# GD32L23x register map
File version: 1.0
CPU: CM23 r0p0, little endian, MPU, FPU, 4 interrupt priority bits
Registers are 32-bit, read-write, reset 0x0 unless marked. A register's access mark holds for its fields unless they carry their own. Offsets are from the block's base; [hi:lo] are bit positions.

## LPTIMER — Low power timers
Base 0x40009400
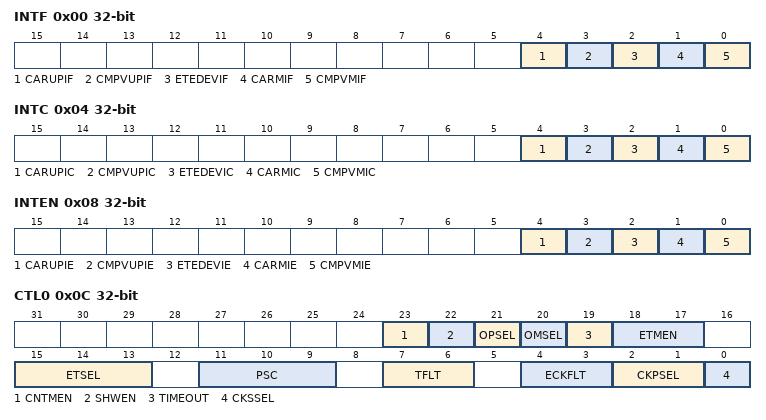
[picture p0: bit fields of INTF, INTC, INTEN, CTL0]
0x00 INTF ro — Interrupt flag register
  [4] CARUPIF — Counter auto reload register update interrupt flag
  [3] CMPVUPIF — Compare value register update interrupt flag
  [2] ETEDEVIF — External trigger edge event interrupt flag
  [1] CARMIF — Counter auto reload register match interrupt flag
  [0] CMPVMIF — Compare value register match interrupt flag
0x04 INTC — Interrupt flag clear register
  [4] CARUPIC — Counter auto reload register update interrupt flag clear
  [3] CMPVUPIC — Compare value register update interrupt flag clear
  [2] ETEDEVIC — External trigger edge event interrupt flag clear
  [1] CARMIC — Counter auto reload register match interrupt flag clear
  [0] CMPVMIC — Compare value register match interrupt flag clear
0x08 INTEN — Interrupt enable register
  [4] CARUPIE — Counter auto reload register update interrupt
  [3] CMPVUPIE — Compare value register update interrupt
  [2] ETEDEVIE — External trigger edge event interrupt
  [1] CARMIE — Counter auto reload register match interrupt
  [0] CMPVMIE — Compare value register match interrupt
0x0C CTL0 — Control register 0
  [23] CNTMEN — Counter mode select
  [22] SHWEN — LPTIMER_CAR and LPTIMER_CMPV shadow registers enable
  [21] OPSEL — Output polarity select
  [20] OMSEL — Output Mode select
  [19] TIMEOUT — Timeout enable
  [18:17] ETMEN — External Trigger mode enable
  [15:13] ETSEL — External trigger select
  [11:9] PSC — Clock prescaler selection
  [7:6] TFLT — Trigger filter
  [4:3] ECKFLT — External clock filter
  [2:1] CKPSEL — Clock polarity select
  [0] CKSSEL — Clock source select
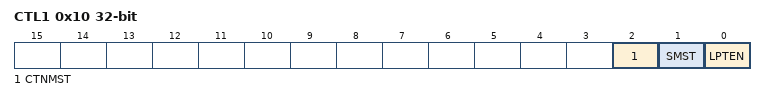
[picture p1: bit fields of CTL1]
0x10 CTL1 — Control register 1
  [2] CTNMST — LPTIMER start in continus counting mode.
  [1] SMST — LPTIMER start in single counting mode
  [0] LPTEN — LPTIMER enable
0x14 CMPV — Compare value register
  [31:0] CMPVAL — Compare value
0x18 CAR — Counter auto reload value
  [31:0] CARL — Low Auto-reload value
0x1C CNT — counter register
  [31:0] CNT — Low counter value
0x20 EIRMP — External input remap register
  [1:0] EI_RMP — External input remap 1

## LPUART — Low-power Universal synchronous asynchronous receiver transmitter
Base 0x40008000
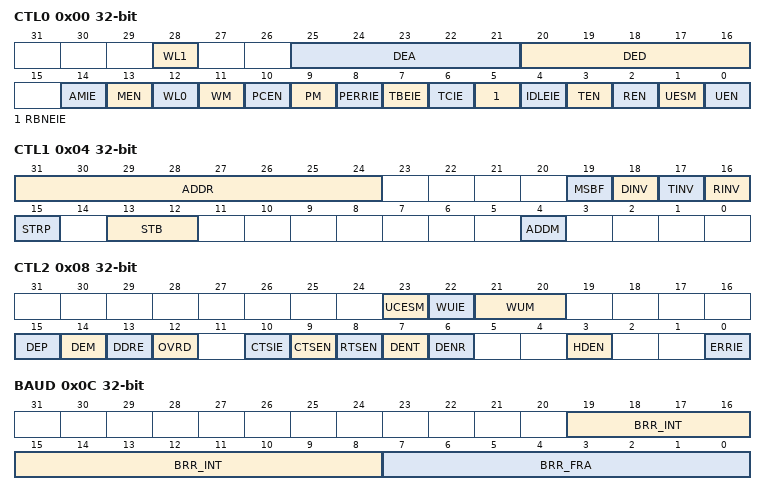
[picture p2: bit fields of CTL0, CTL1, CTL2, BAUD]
0x00 CTL0 — Control register 0
  [28] WL1 — Word length
  [25:21] DEA — Driver Enable assertion time
  [20:16] DED — Driver Enable deassertion time
  [14] AMIE — Character match interrupt enable
  [13] MEN — Mute mode enable
  [12] WL0 — Word length
  [11] WM — Receiver wakeup method
  [10] PCEN — Parity control enable
  [9] PM — Parity selection
  [8] PERRIE — PE interrupt enable
  [7] TBEIE — interrupt enable
  [6] TCIE — Transmission complete interrupt enable
  [5] RBNEIE — RXNE interrupt enable
  [4] IDLEIE — IDLE interrupt enable
  [3] TEN — Transmitter enable
  [2] REN — Receiver enable
  [1] UESM — LPUART enable in Deep-sleep mode
  [0] UEN — USART enable
0x04 CTL1 — Control register 1
  [31:24] ADDR — Address of the USART terminal
  [19] MSBF — Most significant bit first
  [18] DINV — Data bit level inversion
  [17] TINV — TX pin active level inversion
  [16] RINV — RX pin active level inversion
  [15] STRP — Swap TX/RX pins
  [13:12] STB — STOP bits
  [4] ADDM — 7-bit Address Detection/4-bit Address Detection
0x08 CTL2 — Control register 2
  [23] UCESM — LPUART clock enable in Deep-sleep mode
  [22] WUIE — Wakeup from Deep-sleep mode interrupt enable
  [21:20] WUM — Wakeup mode from Deep-sleep mode
  [15] DEP — Driver enable polarity selection
  [14] DEM — Driver enable mode
  [13] DDRE — DMA Disable on Reception Error
  [12] OVRD — Overrun Disable
  [10] CTSIE — CTS interrupt enable
  [9] CTSEN — CTS enable
  [8] RTSEN — RTS enable
  [7] DENT — DMA enable transmitter
  [6] DENR — DMA enable receiver
  [3] HDEN — Half-duplex selection
  [0] ERRIE — Error interrupt enable
0x0C BAUD — Baud rate low register
  [19:8] BRR_INT — integer of baud-rate divider
  [7:0] BRR_FRA — integer of baud-rate divider
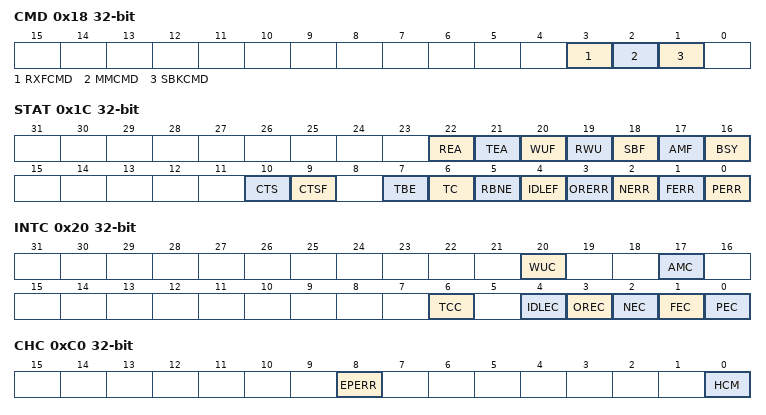
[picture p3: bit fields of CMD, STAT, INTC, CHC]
0x18 CMD wo — Command register
  [3] RXFCMD — Receive data flush command
  [2] MMCMD — Mute mode command
  [1] SBKCMD — Send break command
0x1C STAT ro — Status register
  [22] REA — Receive enable acknowledge flag
  [21] TEA — Transmit enable acknowledge flag
  [20] WUF — Wakeup from Deep-sleep mode flag
  [19] RWU — Receiver wakeup from mute mode
  [18] SBF — Send break flag
  [17] AMF — ADDR match flag
  [16] BSY — Busy flag
  [10] CTS — CTS leve
  [9] CTSF — CTS change flag
  [7] TBE — Transmit data register empty
  [6] TC — Transmission completed
  [5] RBNE — Read data buffer not empty
  [4] IDLEF — IDLE line detected flag
  [3] ORERR — Overrun error
  [2] NERR — Noise error flag
  [1] FERR — Frame error flag
  [0] PERR — Parity error flag
0x20 INTC wo — Interrupt status clear register
  [20] WUC — Wakeup from Deep-sleep mode flag clear
  [17] AMC — ADDR match flag clear
  [6] TCC — Transmission completed clear
  [4] IDLEC — IDLE line detected flag clear
  [3] OREC — Overrun error clear
  [2] NEC — Noise error flag clear
  [1] FEC — Frame error flag clear
  [0] PEC — Parity error flag clear
0x24 RDATA ro — Receive data register
  [8:0] RDATA — Parity error
0x28 TDATA — Transmit data register
  [8:0] TDATA — Transmit data value
0xC0 CHC — coherence control register
  [8] EPERR — Early parity error flag
  [0] HCM — Hardware flow control coherence mode
